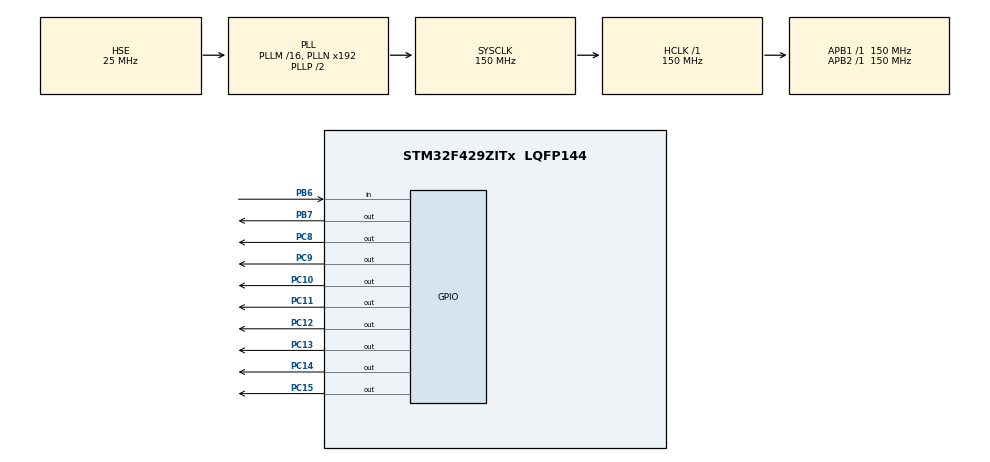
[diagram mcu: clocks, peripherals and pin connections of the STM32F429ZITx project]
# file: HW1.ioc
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Mcu.Family=STM32F4
Mcu.Name=STM32F429ZITx
Mcu.Package=LQFP144
NVIC.PriorityGroup=NVIC_PRIORITYGROUP_4
PB6.Signal=GPIO_Input
PB7.GPIO_Speed=GPIO_SPEED_FREQ_LOW
PB7.Signal=GPIO_Output
PC10.GPIO_Speed=GPIO_SPEED_FREQ_LOW
PC10.Signal=GPIO_Output
PC11.GPIO_Speed=GPIO_SPEED_FREQ_LOW
PC11.Signal=GPIO_Output
PC12.GPIO_Speed=GPIO_SPEED_FREQ_LOW
PC12.Signal=GPIO_Output
PC13.GPIO_Speed=GPIO_SPEED_FREQ_LOW
PC13.PinState=GPIO_PIN_RESET
PC13.Signal=GPIO_Output
PC14/OSC32_IN.Signal=GPIO_Output
PC15/OSC32_OUT.Signal=GPIO_Output
PC8.GPIO_Speed=GPIO_SPEED_FREQ_LOW
PC8.Signal=GPIO_Output
PC9.GPIO_Speed=GPIO_SPEED_FREQ_LOW
PC9.Signal=GPIO_Output
PH0/OSC_IN.Mode=HSE-External-Oscillator
PH0/OSC_IN.Signal=RCC_OSC_IN
PH1/OSC_OUT.Mode=HSE-External-Oscillator
PH1/OSC_OUT.Signal=RCC_OSC_OUT
ProjectManager.HeapSize=0x200
ProjectManager.StackSize=0x400
ProjectManager.TargetToolchain=EWARM V8.32
RCC.48MHZClocksFreq_Value=75000000
RCC.AHBFreq_Value=150000000
RCC.APB1Freq_Value=150000000
RCC.APB1TimFreq_Value=150000000
RCC.APB2Freq_Value=150000000
RCC.APB2TimFreq_Value=150000000
RCC.CortexFreq_Value=150000000
RCC.HCLKFreq_Value=150000000
RCC.HSE_VALUE=25000000
RCC.HSI_VALUE=16000000
RCC.LSE_VALUE=32768
RCC.PLLSourceVirtual=RCC_PLLSOURCE_HSE
RCC.SYSCLKFreq_VALUE=150000000
RCC.SYSCLKSource=RCC_SYSCLKSOURCE_PLLCLK
RCC.VCOOutputFreq_Value=300000000
board=custom

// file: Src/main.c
/* USER CODE BEGIN Header */
/**
  ******************************************************************************
  * @file           : main.c
  * @brief          : Main program body
  ******************************************************************************
  * @attention
  *
  * <h2><center>&copy; Copyright (c) 2020 STMicroelectronics.
  * All rights reserved.</center></h2>
  *
  * This software component is licensed by ST under BSD 3-Clause license,
  * the "License"; You may not use this file except in compliance with the
  * License. You may obtain a copy of the License at:
  *                        opensource.org/licenses/BSD-3-Clause
  *
  ******************************************************************************
  */
/* USER CODE END Header */

#include "main.h"

/* USER CODE BEGIN Includes */
#include "stdbool.h"
/* USER CODE END Includes */

void SystemClock_Config(void);
static void MX_GPIO_Init(void);

int main(void)
{

  uint16_t databus = 0x00FF;  // intializes the data bus at the beginning
  HAL_Init();
  SystemClock_Config();
  MX_GPIO_Init();
  while (1)
  {
    int Start = HAL_GPIO_ReadPin(GPIOB, GPIO_PIN_6);  // always checking for the Start signal
    if (databus  == 0x0000)                           // if statement to reset the databus value
    {
      databus = 0x00FF;
    }
    else {
    }
    if (Start == 1)                                    // if start goes from low to high do this
    {
      HAL_GPIO_WritePin(GPIOB, GPIO_PIN_7, 1);
      databus = databus - 0X0004;
      GPIOC->ODR = databus << 8;

      while (Start == 1) {                            // while start remians high do this
      HAL_GPIO_WritePin(GPIOB, GPIO_PIN_7, 1);
      Start = HAL_GPIO_ReadPin(GPIOB, GPIO_PIN_6);
      GPIOC->ODR = databus << 8;
      }

    }
    else if  (Start == 0){                        // if start is low and remains low do this
      HAL_GPIO_WritePin(GPIOB, GPIO_PIN_7, 0);
      GPIOC->ODR = databus << 8;
    }
  }
  /* USER CODE END 3 */
}

void SystemClock_Config(void)
{
  RCC_OscInitTypeDef RCC_OscInitStruct = {0};
  RCC_ClkInitTypeDef RCC_ClkInitStruct = {0};

  /** Configure the main internal regulator output voltage
  */
  __HAL_RCC_PWR_CLK_ENABLE();
  __HAL_PWR_VOLTAGESCALING_CONFIG(PWR_REGULATOR_VOLTAGE_SCALE2);
  /** Initializes the CPU, AHB and APB busses clocks
  */
  RCC_OscInitStruct.OscillatorType = RCC_OSCILLATORTYPE_HSE;
  RCC_OscInitStruct.HSEState = RCC_HSE_ON;
  RCC_OscInitStruct.PLL.PLLState = RCC_PLL_ON;
  RCC_OscInitStruct.PLL.PLLSource = RCC_PLLSOURCE_HSE;
  RCC_OscInitStruct.PLL.PLLM = 16;
  RCC_OscInitStruct.PLL.PLLN = 192;
  RCC_OscInitStruct.PLL.PLLP = RCC_PLLP_DIV2;
  RCC_OscInitStruct.PLL.PLLQ = 4;
  if (HAL_RCC_OscConfig(&RCC_OscInitStruct) != HAL_OK)
  {
    Error_Handler();
  }
  /** Activate the Over-Drive mode
  */
  if (HAL_PWREx_EnableOverDrive() != HAL_OK)
  {
    Error_Handler();
  }
  /** Initializes the CPU, AHB and APB busses clocks
  */
  RCC_ClkInitStruct.ClockType = RCC_CLOCKTYPE_HCLK|RCC_CLOCKTYPE_SYSCLK
                              |RCC_CLOCKTYPE_PCLK1|RCC_CLOCKTYPE_PCLK2;
  RCC_ClkInitStruct.SYSCLKSource = RCC_SYSCLKSOURCE_PLLCLK;
  RCC_ClkInitStruct.AHBCLKDivider = RCC_SYSCLK_DIV1;
  RCC_ClkInitStruct.APB1CLKDivider = RCC_HCLK_DIV1;
  RCC_ClkInitStruct.APB2CLKDivider = RCC_HCLK_DIV1;

  if (HAL_RCC_ClockConfig(&RCC_ClkInitStruct, FLASH_LATENCY_4) != HAL_OK)
  {
    Error_Handler();
  }
}

static void MX_GPIO_Init(void)
{
  GPIO_InitTypeDef GPIO_InitStruct = {0};

  /* GPIO Ports Clock Enable */
  __HAL_RCC_GPIOC_CLK_ENABLE();
  __HAL_RCC_GPIOH_CLK_ENABLE();
  __HAL_RCC_GPIOB_CLK_ENABLE();

  /*Configure GPIO pin Output Level */
  HAL_GPIO_WritePin(GPIOC, GPIO_PIN_13|GPIO_PIN_14|GPIO_PIN_15|GPIO_PIN_8
                          |GPIO_PIN_9|GPIO_PIN_10|GPIO_PIN_11|GPIO_PIN_12, GPIO_PIN_RESET);

  /*Configure GPIO pin Output Level */
  HAL_GPIO_WritePin(GPIOB, GPIO_PIN_7, GPIO_PIN_RESET);

  /*Configure GPIO pins : PC13 PC14 PC15 PC8
                           PC9 PC10 PC11 PC12 */
  GPIO_InitStruct.Pin = GPIO_PIN_13|GPIO_PIN_14|GPIO_PIN_15|GPIO_PIN_8
                          |GPIO_PIN_9|GPIO_PIN_10|GPIO_PIN_11|GPIO_PIN_12;
  GPIO_InitStruct.Mode = GPIO_MODE_OUTPUT_PP;
  GPIO_InitStruct.Pull = GPIO_NOPULL;
  GPIO_InitStruct.Speed = GPIO_SPEED_FREQ_LOW;
  HAL_GPIO_Init(GPIOC, &GPIO_InitStruct);

  /*Configure GPIO pin : PB6 */
  GPIO_InitStruct.Pin = GPIO_PIN_6;
  GPIO_InitStruct.Mode = GPIO_MODE_Start;
  GPIO_InitStruct.Pull = GPIO_NOPULL;
  HAL_GPIO_Init(GPIOB, &GPIO_InitStruct);

  /*Configure GPIO pin : PB7 */
  GPIO_InitStruct.Pin = GPIO_PIN_7;
  GPIO_InitStruct.Mode = GPIO_MODE_OUTPUT_PP;
  GPIO_InitStruct.Pull = GPIO_NOPULL;
  GPIO_InitStruct.Speed = GPIO_SPEED_FREQ_LOW;
  HAL_GPIO_Init(GPIOB, &GPIO_InitStruct);

}

void Error_Handler(void)
{
}

/************************ (C) COPYRIGHT STMicroelectronics *****END OF FILE****/
